# BearlyML register map
File version: 0.0.1
description_text
CPU: Rocket rv64imac, little endian, no MPU, no FPU, vendor SysTick, 1 interrupt priority bits
Registers are 32-bit, read-write, reset 0x0 unless marked. A register's access mark holds for its fields unless they carry their own. Offsets are from the block's base; lines under a group give offsets from that group; [hi:lo] are bit positions; {n}, {i} and the like mark numbered series; 'fields as' and 'values as' point back to an identical list; <NAME> marks a mode.

## Memory map
0x00000000 DEBUG_CONTROLLER size 0x400
0x00003000 ERROR_DEVICE size 0x400
0x00003000 BOOTSEL size 0x400 — Boot mode selection
0x00110000 RCC size 0x400 — Reset and Clock Control

## RCC — Reset and Clock Control
Base 0x00110000
0x00 CLUSTER_RESETS reset 0x3FF — cluster reset signals
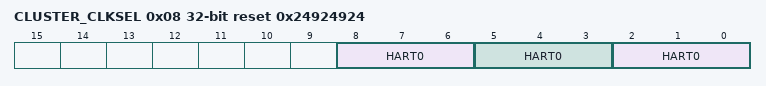
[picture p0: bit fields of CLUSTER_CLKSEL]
0x08 CLUSTER_CLKSEL reset 0x24924924 — cluster reset signals
  [8:6] HART0 — clock select for hart 2
    0=PLL; 1=PLLRefClk; 2=CCLK0; 3=CCLK1; 4=CCLK2; 5=?
  [5:3] HART0 — clock select for hart 1
    0=PLL; 1=PLLRefClk; 2=not useful; 3=not useful; 4=CCLK2; 5=?
  [2:0] HART0 — clock select for hart 0
0x10 BOOT ro — boot select
0x18 SWITCHER_SEL reset 0x1
0x20 HBWIF_RESETS reset 0xFF
0x28 UNCLUSTER_CLKSEL
  [1:0] CLKSEL — clock select
    0=PLL; 1=CCLK2 (DUT CCLK0); 2=CCLK2 (DUT CCLK1); 3=FMC (DUT CCLK2)
0x30 UNCLUSTER_CLKDIV reset 0x4
0x38 LBWIF_CLKDIV reset 0x8
